# AT32F422xx_v2 register map
Vendor: Keil; Series: AT32F422; File version: 1.0
CPU: CM4 r0p1, little endian, no MPU, FPU, 4 interrupt priority bits
Registers are 32-bit, read-write, reset 0x0 unless marked. A register's access mark holds for its fields unless they carry their own. Offsets are from the block's base; [hi:lo] are bit positions; {n}, {i} and the like mark numbered series.

## PWC — Power control
Base 0x40007000
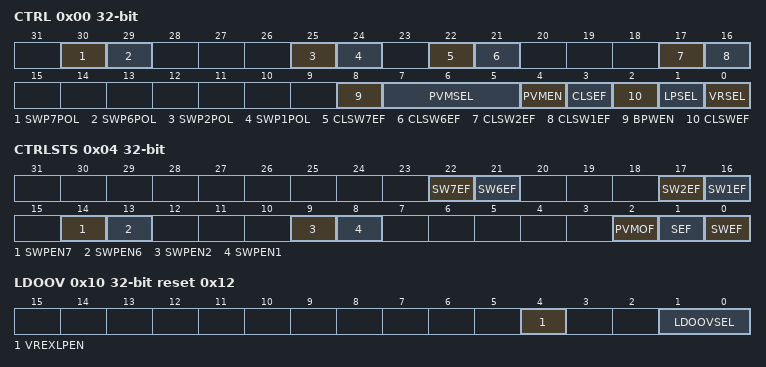
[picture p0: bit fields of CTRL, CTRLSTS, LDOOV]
0x00 CTRL — Power control register (PWC_CTRL)
  [30] SWP7POL — Standby wakeup pin7 polarity
  [29] SWP6POL — Standby wakeup pin6 polarity
  [25] SWP2POL — Standby wakeup pin2 polarity
  [24] SWP1POL — Standby wakeup pin1 polarity
  [22] CLSW7EF — Clear SW3EF flag
  [21] CLSW6EF — Clear SW6EF flag
  [17] CLSW2EF — Clear SW2EF flag
  [16] CLSW1EF — Clear SW1EF flag
  [8] BPWEN — Battery powered domain write enable
  [7:5] PVMSEL — Power voltage monitoring boundary select
  [4] PVMEN — Power voltage monitoring enable
  [3] CLSEF — Clear SEF flag
  [2] CLSWEF — Clear SWEF flag
  [1] LPSEL — Low power mode select when Cortex-M4F sleepdeep
  [0] VRSEL — Voltage regulator state select when deepsleep mode
0x04 CTRLSTS — Power control and status register (PWC_CTRLSTS)
  [22] SW7EF ro — Standby wake-up7 event flag
  [21] SW6EF ro — Standby wake-up6 event flag
  [17] SW2EF ro — Standby wake-up2 event flag
  [16] SW1EF ro — Standby wake-up1 event flag
  [14] SWPEN7 — Standby wake-up pin7 enable
  [13] SWPEN6 — Standby wake-up pin6 enable
  [9] SWPEN2 — Standby wake-up pin2 enable
  [8] SWPEN1 — Standby wake-up pin1 enable
  [2] PVMOF ro — Power voltage monitoring output flag
  [1] SEF ro — Standby mode entry flag
  [0] SWEF ro — Standby wake-up1 event flag
0x10 LDOOV reset 0x12 — LDO output voltage register
  [4] VREXLPEN — Voltage regulator extra low power mode enable
  [1:0] LDOOVSEL — LDO output voltage select

## GPIOA — General purpose I/Os
Base 0x48000000
Same registers: GPIOB 0x48000400, GPIOC 0x48000800, GPIOF 0x48001400
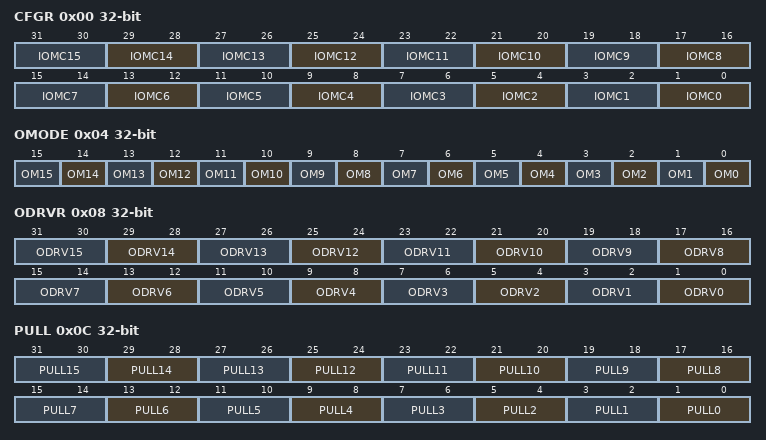
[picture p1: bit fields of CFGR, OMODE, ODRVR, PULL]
0x00 CFGR — GPIO configuration register
  [2n+1:2n] IOMC{n} (n=0..15) — GPIOx pin {n} mode configurate
0x04 OMODE — GPIO output mode register
  [n] OM{n} (n=0..15) — GPIOx pin {n} outpu mode configurate
0x08 ODRVR — GPIO drive capability register
  [2n+1:2n] ODRV{n} (n=0..15) — GPIOx pin {n} output drive capability
0x0C PULL — GPIO pull-up/pull-down register
  [2n+1:2n] PULL{n} (n=0..15) — GPIOx pin {n} pull configuration
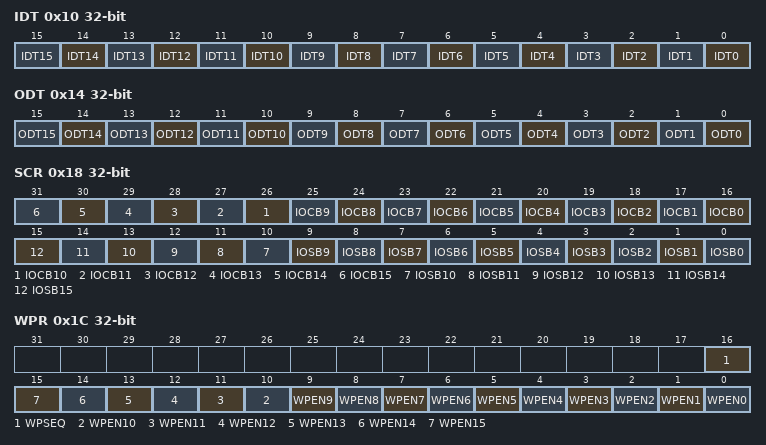
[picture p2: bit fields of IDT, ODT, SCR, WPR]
0x10 IDT ro — GPIO input data register
  [n] IDT{n} (n=0..15) — Port input data
0x14 ODT — GPIO output data register
  [n] ODT{n} (n=0..15) — Port output data
0x18 SCR wo — Port bit set/clear register
  [n+16] IOCB{n} (n=0..15) — Clear bit {n}
  [n] IOSB{n} (n=3..15) — Set bit {n}
  [2] IOSB2 — Set bit 1
  [1] IOSB1 — Set bit 1
  [0] IOSB0 — Set bit 0
0x1C WPR — Port write protect register
  [16] WPSEQ — Write protect sequence
  [n] WPEN{n} (n=0..15) — Write protect enable {n}
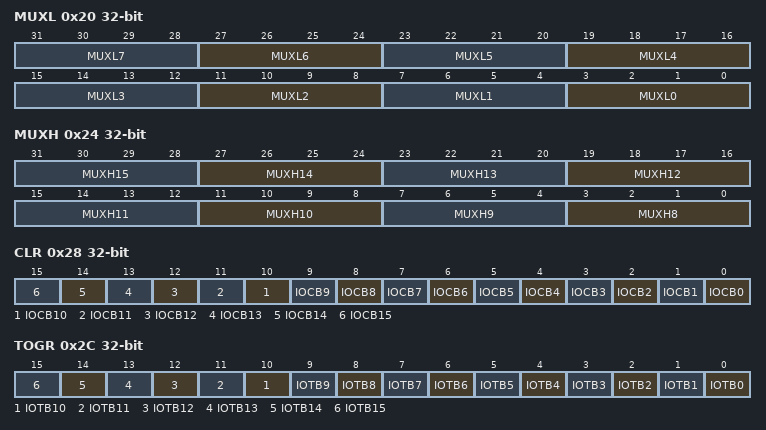
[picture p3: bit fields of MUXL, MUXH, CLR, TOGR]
0x20 MUXL — GPIO muxing function low register
  [4n+3:4n] MUXL{n} (n=0..7) — GPIOx pin {n} muxing
0x24 MUXH — GPIO muxing function high register
  [4n-29:4n-32] MUXH{n} (n=8..15) — GPIOx pin {n} muxing
0x28 CLR wo — GPIO bit reset register
  [n] IOCB{n} (n=0..15) — Clear bit {n}
0x2C TOGR wo — GPIO bit toggle register
  [n] IOTB{n} (n=0..15) — Toggle bit {n}
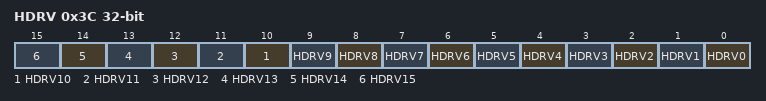
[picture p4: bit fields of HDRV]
0x3C HDRV — Huge current driver
  [n] HDRV{n} (n=0..15) — Port x driver bit y

## EXINT
Base 0x40010400
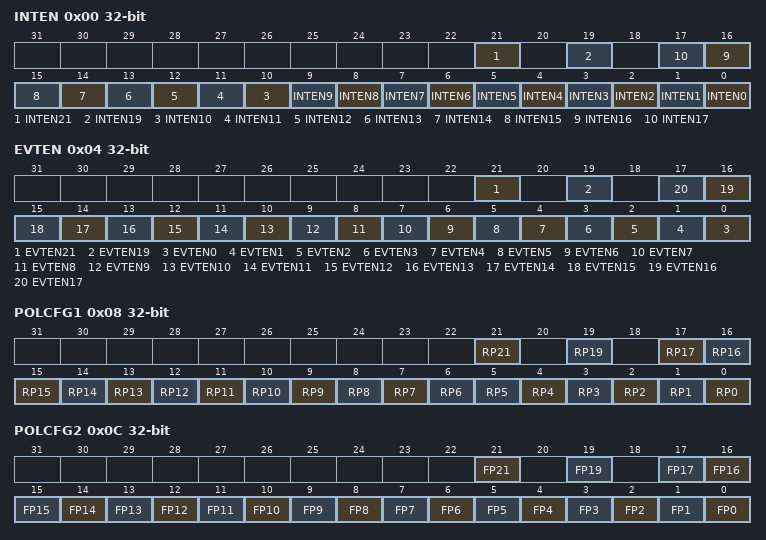
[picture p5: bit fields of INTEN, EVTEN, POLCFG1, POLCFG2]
0x00 INTEN — Interrupt enable register
  [21] INTEN21 — Interrupt enable or disable on line 21
  [19] INTEN19 — Interrupt enable or disable on line 19
  [n] INTEN{n} (n=0..17) — Interrupt enable or disable on line {n}
0x04 EVTEN — Event enable register
  [21] EVTEN21 — Event enable or disable on line 21
  [19] EVTEN19 — Event enable or disable on line 19
  [n] EVTEN{n} (n=0..17) — Event enable or disable on line {n}
0x08 POLCFG1 — Rising polarity configuration register
  [21] RP21 — Rising polarity configuration bit of line 21
  [19] RP19 — Rising polarity configuration bit of line 19
  [n] RP{n} (n=7..17) — Rising polarity configuration bit of line {n}
  [6] RP6 — Rising polarity configuration bit of linee 6
  [n] RP{n} (n=0..5) — Rising polarity configuration bit of line {n}
0x0C POLCFG2 — Falling polarity configuration register
  [21] FP21 — Falling polarity event configuration bit of line 21
  [19] FP19 — Falling polarity event configuration bit of line 19
  [n] FP{n} (n=0..17) — Falling polarity event configuration bit of line {n}
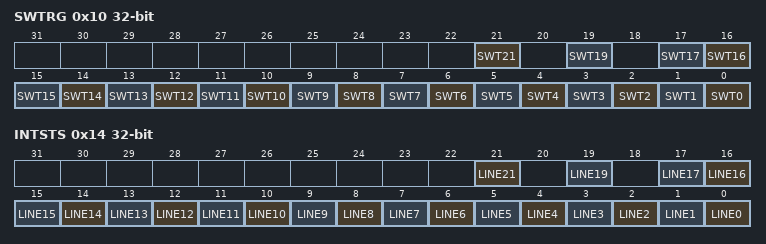
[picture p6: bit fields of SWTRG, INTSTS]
0x10 SWTRG — Software triggle register
  [21] SWT21 — Software triggle on line 21
  [19] SWT19 — Software triggle on line 19
  [n] SWT{n} (n=0..17) — Software triggle on line {n}
0x14 INTSTS — Interrupt status register
  [21] LINE21 — Line 21 state bit
  [19] LINE19 — Line 19 state bit
  [n] LINE{n} (n=0..17) — Line {n} state bit

## Notices in the file
Copyright (C) 2012-2014 ARM Limited. All rights reserved.
Purpose: System Viewer Description (SVD) Example (Schema Version 1.1)
This is a description of a none-existent and incomplete device
for demonstration purposes only.
Redistribution and use in source and binary forms, with or without
modification, are permitted provided that the following conditions are met:
- Redistributions of source code must retain the above copyright
notice, this list of conditions and the following disclaimer.
- Redistributions in binary form must reproduce the above copyright
notice, this list of conditions and the following disclaimer in the
documentation and/or other materials provided with the distribution.
- Neither the name of ARM nor the names of its contributors may be used
to endorse or promote products derived from this software without
specific prior written permission.
THIS SOFTWARE IS PROVIDED BY THE COPYRIGHT HOLDERS AND CONTRIBUTORS "AS IS"
AND ANY EXPRESS OR IMPLIED WARRANTIES, INCLUDING, BUT NOT LIMITED TO, THE
IMPLIED WARRANTIES OF MERCHANTABILITY AND FITNESS FOR A PARTICULAR PURPOSE
ARE DISCLAIMED. IN NO EVENT SHALL COPYRIGHT HOLDERS AND CONTRIBUTORS BE
LIABLE FOR ANY DIRECT, INDIRECT, INCIDENTAL, SPECIAL, EXEMPLARY, OR
CONSEQUENTIAL DAMAGES (INCLUDING, BUT NOT LIMITED TO, PROCUREMENT OF
SUBSTITUTE GOODS OR SERVICES; LOSS OF USE, DATA, OR PROFITS; OR BUSINESS
INTERRUPTION) HOWEVER CAUSED AND ON ANY THEORY OF LIABILITY, WHETHER IN
CONTRACT, STRICT LIABILITY, OR TORT (INCLUDING NEGLIGENCE OR OTHERWISE)
ARISING IN ANY WAY OUT OF THE USE OF THIS SOFTWARE, EVEN IF ADVISED OF THE
POSSIBILITY OF SUCH DAMAGE.
